# STM32F103xx register map
File version: 1.3
STM32F103xx, GPIOA, USART1 and USART2 only: a test excerpt of cmsis-svd-data's STM32F103xx.svd
Registers are 32-bit, read-write, reset 0x0 unless marked. A register's access mark holds for its fields unless they carry their own. Offsets are from the block's base; lines under a group give offsets from that group; [hi:lo] are bit positions; {n}, {i} and the like mark numbered series; 'fields as' and 'values as' point back to an identical list; <NAME> marks a mode.

## Memory map
0x40004400 USART2 size 0x400
0x40010800 GPIOA size 0x400 — General purpose I/O
0x40013800 USART1 size 0x400 — Universal synchronous asynchronous receiver transmitter

## Interrupts
37 USART1 — USART1 global interrupt
38 USART2 — USART2 global interrupt

## GPIOA — General purpose I/O
Base 0x40010800
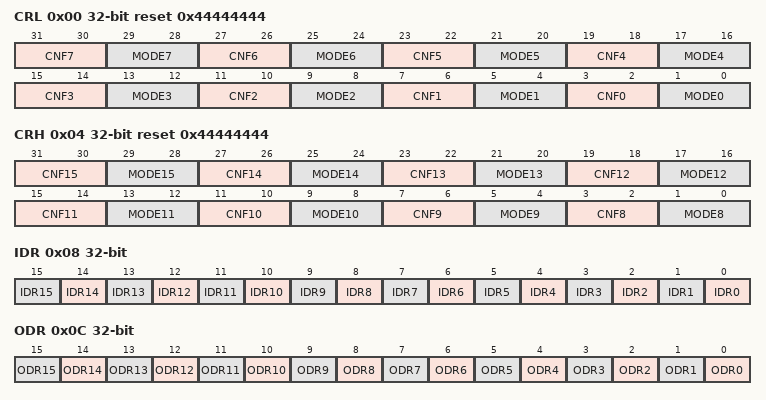
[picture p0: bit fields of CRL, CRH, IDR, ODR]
0x00 CRL reset 0x44444444 — Port configuration register low (GPIOn_CRL)
  [31:30] CNF7 — Port n.7 configuration bits
  [29:28] MODE7 — Port n.7 mode bits
  [27:26] CNF6 — Port n.6 configuration bits
  [25:24] MODE6 — Port n.6 mode bits
  [23:22] CNF5 — Port n.5 configuration bits
  [21:20] MODE5 — Port n.5 mode bits
  [19:18] CNF4 — Port n.4 configuration bits
  [17:16] MODE4 — Port n.4 mode bits
  [15:14] CNF3 — Port n.3 configuration bits
  [13:12] MODE3 — Port n.3 mode bits
  [11:10] CNF2 — Port n.2 configuration bits
  [9:8] MODE2 — Port n.2 mode bits
  [7:6] CNF1 — Port n.1 configuration bits
  [5:4] MODE1 — Port n.1 mode bits
  [3:2] CNF0 — Port n.0 configuration bits
  [1:0] MODE0 — Port n.0 mode bits
0x04 CRH reset 0x44444444 — Port configuration register high (GPIOn_CRL)
  [31:30] CNF15 — Port n.15 configuration bits
  [29:28] MODE15 — Port n.15 mode bits
  [27:26] CNF14 — Port n.14 configuration bits
  [25:24] MODE14 — Port n.14 mode bits
  [23:22] CNF13 — Port n.13 configuration bits
  [21:20] MODE13 — Port n.13 mode bits
  [19:18] CNF12 — Port n.12 configuration bits
  [17:16] MODE12 — Port n.12 mode bits
  [15:14] CNF11 — Port n.11 configuration bits
  [13:12] MODE11 — Port n.11 mode bits
  [11:10] CNF10 — Port n.10 configuration bits
  [9:8] MODE10 — Port n.10 mode bits
  [7:6] CNF9 — Port n.9 configuration bits
  [5:4] MODE9 — Port n.9 mode bits
  [3:2] CNF8 — Port n.8 configuration bits
  [1:0] MODE8 — Port n.8 mode bits
0x08 IDR ro — Port input data register (GPIOn_IDR)
  [n] IDR{n} (n=0..15) — Port input data
0x0C ODR — Port output data register (GPIOn_ODR)
  [n] ODR{n} (n=0..15) — Port output data
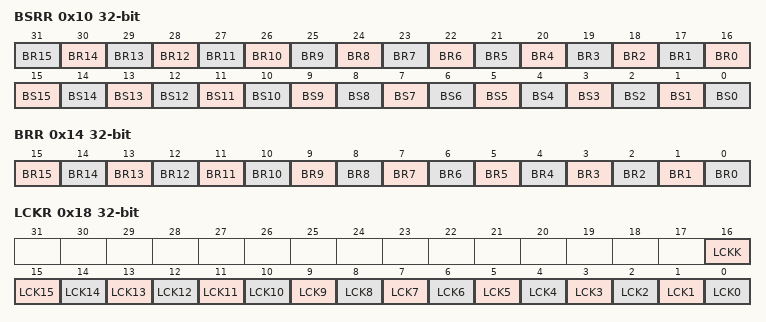
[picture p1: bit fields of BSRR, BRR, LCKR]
0x10 BSRR wo — Port bit set/reset register (GPIOn_BSRR)
  [n+16] BR{n} (n=0..15) — Reset bit {n}
  [n] BS{n} (n=3..15) — Set bit {n}
  [2] BS2 — Set bit 1
  [1] BS1 — Set bit 1
  [0] BS0 — Set bit 0
0x14 BRR wo — Port bit reset register (GPIOn_BRR)
  [n] BR{n} (n=3..15) — Reset bit {n}
  [2] BR2 — Reset bit 1
  [1] BR1 — Reset bit 1
  [0] BR0 — Reset bit 0
0x18 LCKR — Port configuration lock register
  [16] LCKK — Lock key
  [n] LCK{n} (n=0..15) — Port A Lock bit {n}

## USART1 — Universal synchronous asynchronous receiver transmitter
Base 0x40013800
Same registers: USART2 0x40004400
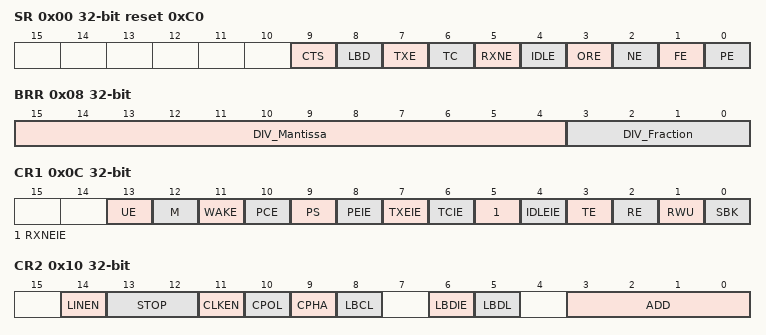
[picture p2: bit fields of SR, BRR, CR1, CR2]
0x00 SR access per field reset 0xC0 — Status register
  [9] CTS rw — CTS flag
  [8] LBD rw — LIN break detection flag
  [7] TXE ro — Transmit data register empty
  [6] TC rw — Transmission complete
  [5] RXNE rw — Read data register not empty
  [4] IDLE ro — IDLE line detected
  [3] ORE ro — Overrun error
  [2] NE ro — Noise error flag
  [1] FE ro — Framing error
  [0] PE ro — Parity error
0x04 DR — Data register
  [8:0] DR — Data value
0x08 BRR — Baud rate register
  [15:4] DIV_Mantissa — mantissa of USARTDIV
  [3:0] DIV_Fraction — fraction of USARTDIV
0x0C CR1 — Control register 1
  [13] UE — USART enable
  [12] M — Word length
  [11] WAKE — Wakeup method
  [10] PCE — Parity control enable
  [9] PS — Parity selection
  [8] PEIE — PE interrupt enable
  [7] TXEIE — TXE interrupt enable
  [6] TCIE — Transmission complete interrupt enable
  [5] RXNEIE — RXNE interrupt enable
  [4] IDLEIE — IDLE interrupt enable
  [3] TE — Transmitter enable
  [2] RE — Receiver enable
  [1] RWU — Receiver wakeup
  [0] SBK — Send break
0x10 CR2 — Control register 2
  [14] LINEN — LIN mode enable
  [13:12] STOP — STOP bits
  [11] CLKEN — Clock enable
  [10] CPOL — Clock polarity
  [9] CPHA — Clock phase
  [8] LBCL — Last bit clock pulse
  [6] LBDIE — LIN break detection interrupt enable
  [5] LBDL — lin break detection length
  [3:0] ADD — Address of the USART node
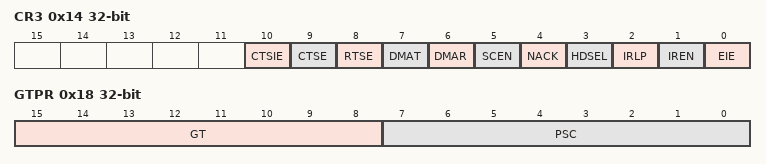
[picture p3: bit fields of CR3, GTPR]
0x14 CR3 — Control register 3
  [10] CTSIE — CTS interrupt enable
  [9] CTSE — CTS enable
  [8] RTSE — RTS enable
  [7] DMAT — DMA enable transmitter
  [6] DMAR — DMA enable receiver
  [5] SCEN — Smartcard mode enable
  [4] NACK — Smartcard NACK enable
  [3] HDSEL — Half-duplex selection
  [2] IRLP — IrDA low-power
  [1] IREN — IrDA mode enable
  [0] EIE — Error interrupt enable
0x18 GTPR — Guard time and prescaler register
  [15:8] GT — Guard time value
  [7:0] PSC — Prescaler value
